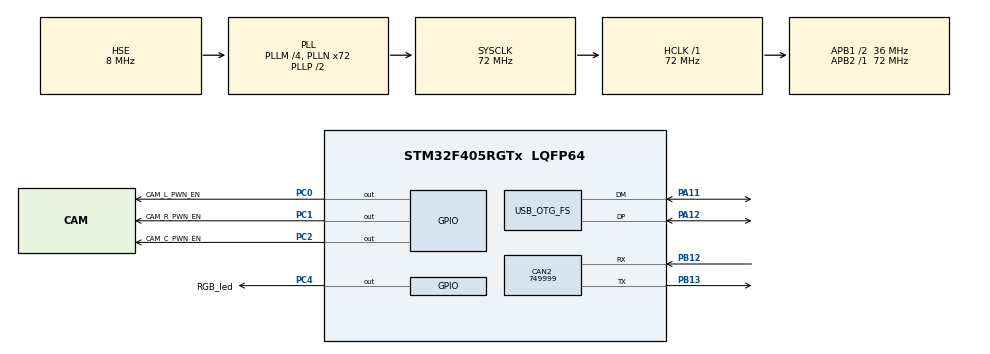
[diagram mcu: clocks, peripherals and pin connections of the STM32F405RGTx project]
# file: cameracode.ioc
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CAN2.CalculateBaudRate=749999
CAN2.CalculateTimeBit=1333
CAN2.CalculateTimeQuantum=444.44444444444446
Mcu.Family=STM32F4
Mcu.Name=STM32F405RGTx
Mcu.Package=LQFP64
NVIC.PriorityGroup=NVIC_PRIORITYGROUP_4
PA0-WKUP.GPIO_Label=cameratx
PA0-WKUP.Signal=UART4_TX
PA11.Mode=Device_Only
PA11.Signal=USB_OTG_FS_DM
PA12.Mode=Device_Only
PA12.Signal=USB_OTG_FS_DP
PA13.Mode=Serial_Wire
PA13.Signal=SYS_JTMS-SWDIO
PA14.Mode=Serial_Wire
PA14.Signal=SYS_JTCK-SWCLK
PB12.Mode=CAN_Activate
PB12.Signal=CAN2_RX
PB13.Mode=CAN_Activate
PB13.Signal=CAN2_TX
PC0.GPIO_Label=CAM_L_PWN_EN
PC0.Signal=GPIO_Output
PC1.GPIO_Label=CAM_R_PWN_EN
PC1.Signal=GPIO_Output
PC2.GPIO_Label=CAM_C_PWN_EN
PC2.Signal=GPIO_Output
PC4.GPIO_Label=RGB_led
PC4.Signal=GPIO_Output
PH0-OSC_IN.Mode=HSE-External-Oscillator
PH0-OSC_IN.Signal=RCC_OSC_IN
PH1-OSC_OUT.Mode=HSE-External-Oscillator
PH1-OSC_OUT.Signal=RCC_OSC_OUT
ProjectManager.HeapSize=0x200
ProjectManager.StackSize=0x400
ProjectManager.TargetToolchain=CMake
RCC.48MHZClocksFreq_Value=48000000
RCC.AHBFreq_Value=72000000
RCC.APB1CLKDivider=RCC_HCLK_DIV2
RCC.APB1Freq_Value=36000000
RCC.APB1TimFreq_Value=72000000
RCC.APB2Freq_Value=72000000
RCC.APB2TimFreq_Value=72000000
RCC.CortexFreq_Value=72000000
RCC.HCLKFreq_Value=72000000
RCC.HSE_VALUE=8000000
RCC.HSI_VALUE=16000000
RCC.LSE_VALUE=32768
RCC.PLLM=4
RCC.PLLN=72
RCC.PLLQ=3
RCC.SYSCLKFreq_VALUE=72000000
RCC.SYSCLKSource=RCC_SYSCLKSOURCE_PLLCLK
RCC.VCOOutputFreq_Value=144000000
USB_OTG_FS.VirtualMode=Device_Only
UART4.BaudRate=115200
UART4.VirtualMode=VM_ASYNC
board=custom

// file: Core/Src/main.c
/* USER CODE BEGIN Header */
/**
  ******************************************************************************
  * @file           : main.c
  * @brief          : Main program body
  ******************************************************************************
  * @attention
  *
  * Copyright (c) 2026 STMicroelectronics.
  * All rights reserved.
  *
  * This software is licensed under terms that can be found in the LICENSE file
  * in the root directory of this software component.
  * If no LICENSE file comes with this software, it is provided AS-IS.
  *
  ******************************************************************************
  */
/* USER CODE END Header */
#include "main.h"

/* USER CODE BEGIN Includes */
#include "camera_board_app.h"
#include "camera_board_config.h"

/* USER CODE END Includes */

CAN_HandleTypeDef hcan2;

UART_HandleTypeDef huart4;

PCD_HandleTypeDef hpcd_USB_OTG_FS;

void SystemClock_Config(void);
static void MX_GPIO_Init(void);
static void MX_CAN2_Init(void);
static void MX_UART4_Init(void);
static void MX_USB_OTG_FS_PCD_Init(void);

int main(void)
{

  /* MCU Configuration--------------------------------------------------------*/

  /* Reset of all peripherals, Initializes the Flash interface and the Systick. */
  HAL_Init();

  /* Configure the system clock */
  SystemClock_Config();

  /* Initialize all configured peripherals */
  MX_GPIO_Init();
  MX_CAN2_Init();
  MX_UART4_Init();
  MX_USB_OTG_FS_PCD_Init();
  /* USER CODE BEGIN 2 */
  CameraBoard_AppConfig_t app_config =
  {
    .camera_uart = &huart4,
    .output_uart = &huart4
  };

  CameraBoard_AppInit(&app_config);

  /* USER CODE END 2 */

  /* Infinite loop */
  while (1)
  {

    /* USER CODE BEGIN 3 */
    CameraBoard_AppRun();
  }
  /* USER CODE END 3 */
}

void SystemClock_Config(void)
{
  RCC_OscInitTypeDef RCC_OscInitStruct = {0};
  RCC_ClkInitTypeDef RCC_ClkInitStruct = {0};

  /** Configure the main internal regulator output voltage
  */
  __HAL_RCC_PWR_CLK_ENABLE();
  __HAL_PWR_VOLTAGESCALING_CONFIG(PWR_REGULATOR_VOLTAGE_SCALE1);

  /** Initializes the RCC Oscillators according to the specified parameters
  * in the RCC_OscInitTypeDef structure.
  */
  RCC_OscInitStruct.OscillatorType = RCC_OSCILLATORTYPE_HSE;
  RCC_OscInitStruct.HSEState = RCC_HSE_ON;
  RCC_OscInitStruct.PLL.PLLState = RCC_PLL_ON;
  RCC_OscInitStruct.PLL.PLLSource = RCC_PLLSOURCE_HSE;
  RCC_OscInitStruct.PLL.PLLM = 4;
  RCC_OscInitStruct.PLL.PLLN = 72;
  RCC_OscInitStruct.PLL.PLLP = RCC_PLLP_DIV2;
  RCC_OscInitStruct.PLL.PLLQ = 3;
  if (HAL_RCC_OscConfig(&RCC_OscInitStruct) != HAL_OK)
  {
    Error_Handler();
  }

  /** Initializes the CPU, AHB and APB buses clocks
  */
  RCC_ClkInitStruct.ClockType = RCC_CLOCKTYPE_HCLK|RCC_CLOCKTYPE_SYSCLK
                              |RCC_CLOCKTYPE_PCLK1|RCC_CLOCKTYPE_PCLK2;
  RCC_ClkInitStruct.SYSCLKSource = RCC_SYSCLKSOURCE_PLLCLK;
  RCC_ClkInitStruct.AHBCLKDivider = RCC_SYSCLK_DIV1;
  RCC_ClkInitStruct.APB1CLKDivider = RCC_HCLK_DIV2;
  RCC_ClkInitStruct.APB2CLKDivider = RCC_HCLK_DIV1;

  if (HAL_RCC_ClockConfig(&RCC_ClkInitStruct, FLASH_LATENCY_2) != HAL_OK)
  {
    Error_Handler();
  }
}

static void MX_UART4_Init(void)
{

  huart4.Instance = UART4;
  huart4.Init.BaudRate = CAMERA_BOARD_CAMERA_UART_BAUD_RATE;
  huart4.Init.WordLength = UART_WORDLENGTH_8B;
  huart4.Init.StopBits = UART_STOPBITS_1;
  huart4.Init.Parity = UART_PARITY_NONE;
  huart4.Init.Mode = UART_MODE_TX;
  huart4.Init.HwFlowCtl = UART_HWCONTROL_NONE;
  huart4.Init.OverSampling = UART_OVERSAMPLING_16;
  if (HAL_UART_Init(&huart4) != HAL_OK)
  {
    Error_Handler();
  }

}

static void MX_CAN2_Init(void)
{

  hcan2.Instance = CAN2;
  hcan2.Init.Prescaler = 16;
  hcan2.Init.Mode = CAN_MODE_NORMAL;
  hcan2.Init.SyncJumpWidth = CAN_SJW_1TQ;
  hcan2.Init.TimeSeg1 = CAN_BS1_1TQ;
  hcan2.Init.TimeSeg2 = CAN_BS2_1TQ;
  hcan2.Init.TimeTriggeredMode = DISABLE;
  hcan2.Init.AutoBusOff = DISABLE;
  hcan2.Init.AutoWakeUp = DISABLE;
  hcan2.Init.AutoRetransmission = DISABLE;
  hcan2.Init.ReceiveFifoLocked = DISABLE;
  hcan2.Init.TransmitFifoPriority = DISABLE;
  if (HAL_CAN_Init(&hcan2) != HAL_OK)
  {
    Error_Handler();
  }

}

static void MX_USB_OTG_FS_PCD_Init(void)
{

  hpcd_USB_OTG_FS.Instance = USB_OTG_FS;
  hpcd_USB_OTG_FS.Init.dev_endpoints = 4;
  hpcd_USB_OTG_FS.Init.speed = PCD_SPEED_FULL;
  hpcd_USB_OTG_FS.Init.dma_enable = DISABLE;
  hpcd_USB_OTG_FS.Init.phy_itface = PCD_PHY_EMBEDDED;
  hpcd_USB_OTG_FS.Init.Sof_enable = DISABLE;
  hpcd_USB_OTG_FS.Init.low_power_enable = DISABLE;
  hpcd_USB_OTG_FS.Init.lpm_enable = DISABLE;
  hpcd_USB_OTG_FS.Init.vbus_sensing_enable = DISABLE;
  hpcd_USB_OTG_FS.Init.use_dedicated_ep1 = DISABLE;
  if (HAL_PCD_Init(&hpcd_USB_OTG_FS) != HAL_OK)
  {
    Error_Handler();
  }

}

static void MX_GPIO_Init(void)
{
  GPIO_InitTypeDef GPIO_InitStruct = {0};

  /* GPIO Ports Clock Enable */
  __HAL_RCC_GPIOH_CLK_ENABLE();
  __HAL_RCC_GPIOC_CLK_ENABLE();
  __HAL_RCC_GPIOA_CLK_ENABLE();
  __HAL_RCC_GPIOB_CLK_ENABLE();

  /*Configure GPIO pin Output Level */
  HAL_GPIO_WritePin(GPIOC, CAM_L_PWN_EN_Pin|CAM_R_PWN_EN_Pin|CAM_C_PWN_EN_Pin, GPIO_PIN_SET);
  HAL_GPIO_WritePin(GPIOC, RGB_led_Pin, GPIO_PIN_RESET);

  /*Configure GPIO pins : CAM_L_PWN_EN_Pin CAM_R_PWN_EN_Pin CAM_C_PWN_EN_Pin RGB_led_Pin */
  GPIO_InitStruct.Pin = CAM_L_PWN_EN_Pin|CAM_R_PWN_EN_Pin|CAM_C_PWN_EN_Pin|RGB_led_Pin;
  GPIO_InitStruct.Mode = GPIO_MODE_OUTPUT_PP;
  GPIO_InitStruct.Pull = GPIO_NOPULL;
  GPIO_InitStruct.Speed = GPIO_SPEED_FREQ_LOW;
  HAL_GPIO_Init(GPIOC, &GPIO_InitStruct);

}

void Error_Handler(void)
{
  __disable_irq();
  while (1)
  {
  }
}
